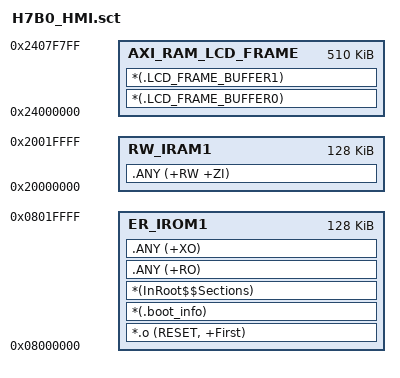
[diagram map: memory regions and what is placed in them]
; *************************************************************
; *** Scatter-Loading Description File generated by uVision ***
; *************************************************************

LR_IROM1 0x08000000 0x00020000  {    ; load region size_region
  ER_IROM1 0x08000000 0x00020000  {  ; load address = execution address
   *.o (RESET, +First)
   *(.boot_info)
   *(InRoot$$Sections)
   .ANY (+RO)
   .ANY (+XO)
  }
  RW_IRAM1 0x20000000 0x00020000  {  ; RW data
   .ANY (+RW +ZI)
  }
  AXI_RAM_LCD_FRAME 0x24000000  0x0007F800  {
	*(.LCD_FRAME_BUFFER0)
	*(.LCD_FRAME_BUFFER1)
  }
}

